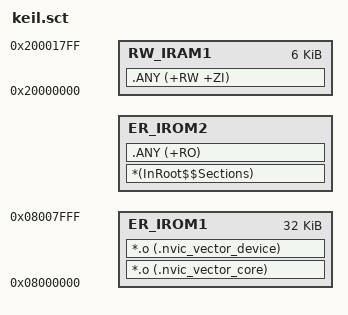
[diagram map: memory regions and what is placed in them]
; *************************************************************
; *** Scatter-Loading Description File generated by uVision ***
; *************************************************************

LR_IROM1 0x08000000 0x00008000  {    ; load region size_region
  ER_IROM1 0x08000000 0x00008000  {  ; load address = execution address
   *.o (.nvic_vector_core)
   *.o (.nvic_vector_device)
  }
  ER_IROM2 +0 {
   *(InRoot$$Sections)
   .ANY (+RO)
  }
  RW_IRAM1 0x20000000 0x00001800  {  ; RW data
   .ANY (+RW +ZI)
  }
}


